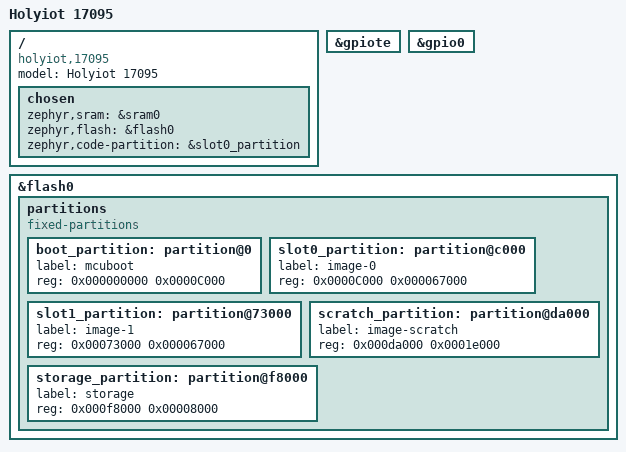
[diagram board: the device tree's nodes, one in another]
/*
 * Copyright (c) 2019 Henrik Brix Andersen <henrik@brixandersen.dk>
 *
 * SPDX-License-Identifier: Apache-2.0
 */

/dts-v1/;
#include <nordic/nrf52832_qfaa.dtsi>

/ {
	model = "Holyiot 17095";
	compatible = "holyiot,17095", "nordic,nrf52832-qfaa",
		     "nordic,nrf52832";

	chosen {
		zephyr,sram = &sram0;
		zephyr,flash = &flash0;
		zephyr,code-partition = &slot0_partition;
	};
};

&gpiote {
	status = "okay";
};

&gpio0 {
	status = "okay";
};

&flash0 {
	/*
	 * For more information, see:
	 * http://docs.zephyrproject.org/latest/guides/dts/index.html#flash-partitions
	 */
	partitions {
		compatible = "fixed-partitions";
		#address-cells = <1>;
		#size-cells = <1>;

		boot_partition: partition@0 {
			label = "mcuboot";
			reg = <0x000000000 0x0000C000>;
		};
		slot0_partition: partition@c000 {
			label = "image-0";
			reg = <0x0000C000 0x000067000>;
		};
		slot1_partition: partition@73000 {
			label = "image-1";
			reg = <0x00073000 0x000067000>;
		};
		scratch_partition: partition@da000 {
			label = "image-scratch";
			reg = <0x000da000 0x0001e000>;
		};

		/*
		 * The flash starting at 0x000f8000 and ending at
		 * 0x000fffff is reserved for use by the application.
		 */

		/* Storage partition will be used by FCB/NFFS/NVS if enabled. */
		storage_partition: partition@f8000 {
			label = "storage";
			reg = <0x000f8000 0x00008000>;
		};
	};
};
